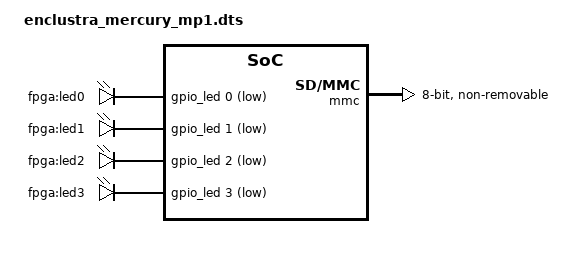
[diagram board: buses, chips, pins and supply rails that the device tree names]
// SPDX-License-Identifier: (GPL-2.0+ OR MIT)
/*
 * Copyright (C) 2025 Enclustra GmbH
 * <info@enclustra.com>
 */

/dts-v1/;

#include "enclustra_mercury_mp1.dtsi"
#include "enclustra_mercury_mp1_fabric.dtsi"
#include <dt-bindings/gpio/gpio.h>

/ {
	leds {
		compatible = "gpio-leds";

		led0 {
			label = "fpga:led0";
			gpios = <&gpio_led 0 GPIO_ACTIVE_LOW>;
			linux,default-trigger = "heartbeat";
		};

		led1 {
			label = "fpga:led1";
			gpios = <&gpio_led 1 GPIO_ACTIVE_LOW>;
			linux,default-trigger = "activity";
		};

		led2 {
			label = "fpga:led2";
			gpios = <&gpio_led 2 GPIO_ACTIVE_LOW>;
			linux,default-trigger = "none";
		};

		led3 {
			label = "fpga:led3";
			gpios = <&gpio_led 3 GPIO_ACTIVE_LOW>;
			linux,default-trigger = "none";
		};
	};
};

&mmc {
	bus-width = <8>;
	non-removable;
	cap-mmc-highspeed;
	no-1-8-v;

	/delete-property/ card-detect-delay;
	/delete-property/ cap-sd-highspeed;
};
